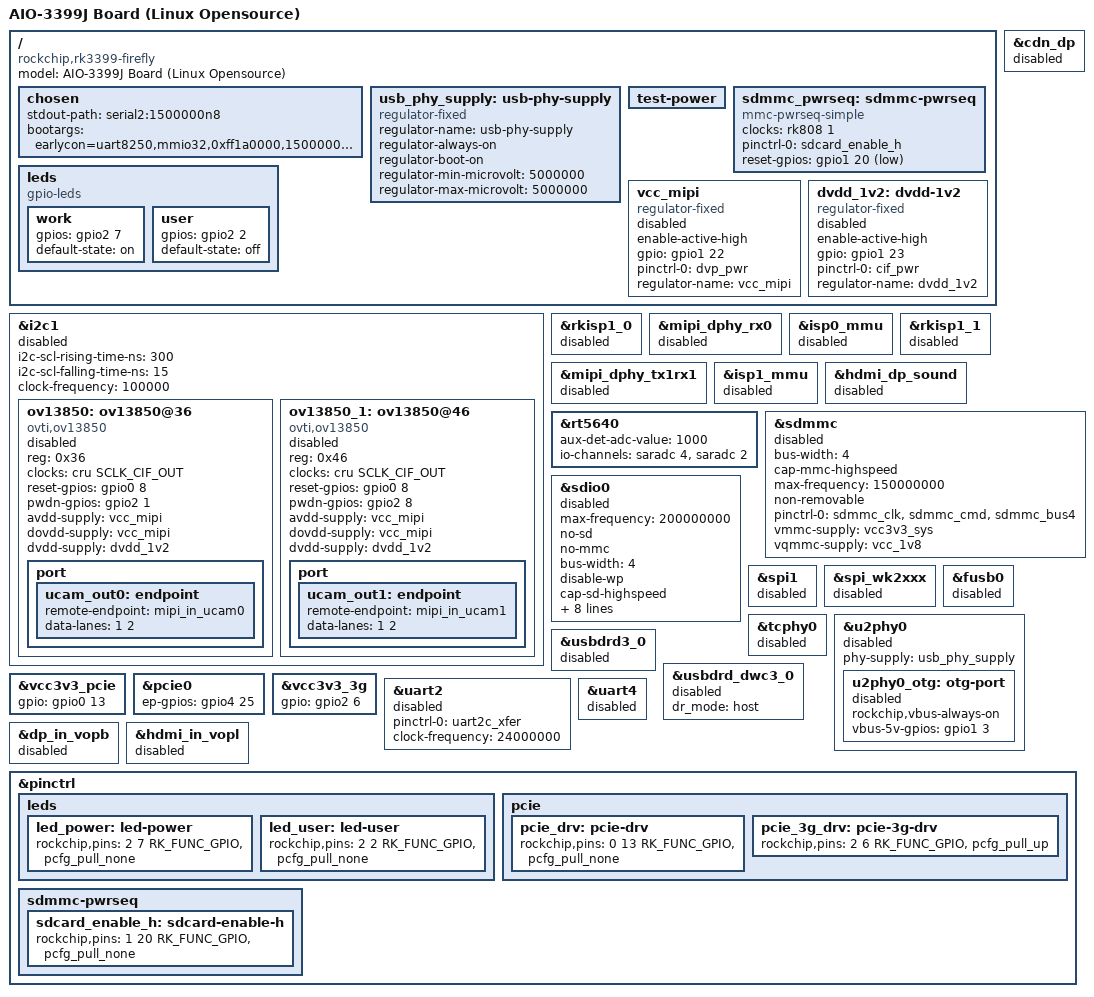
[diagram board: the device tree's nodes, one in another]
/*
 * Copyright (c) 2016 Fuzhou Rockchip Electronics Co., Ltd
 *
 * This file is dual-licensed: you can use it either under the terms
 * of the GPL or the X11 license, at your option. Note that this dual
 * licensing only applies to this file, and not this project as a
 * whole.
 *
 *  a) This file is free software; you can redistribute it and/or
 *     modify it under the terms of the GNU General Public License as
 *     published by the Free Software Foundation; either version 2 of the
 *     License, or (at your option) any later version.
 *
 *     This file is distributed in the hope that it will be useful,
 *     but WITHOUT ANY WARRANTY; without even the implied warranty of
 *     MERCHANTABILITY or FITNESS FOR A PARTICULAR PURPOSE.  See the
 *     GNU General Public License for more details.
 *
 * Or, alternatively,
 *     restriction, including without limitation the rights to use,
 *     copy, modify, merge, publish, distribute, sublicense, and/or
 *     sell copies of the Software, and to permit persons to whom the
 *     Software is furnished to do so, subject to the following
 *     conditions:
 *
 *     The above copyright notice and this permission notice shall be
 *     included in all copies or substantial portions of the Software.
 *
 *     THE SOFTWARE IS PROVIDED "AS IS", WITHOUT WARRANTY OF ANY KIND,
 *     EXPRESS OR IMPLIED, INCLUDING BUT NOT LIMITED TO THE WARRANTIES
 *     OF MERCHANTABILITY, FITNESS FOR A PARTICULAR PURPOSE AND
 *     NONINFRINGEMENT. IN NO EVENT SHALL THE AUTHORS OR COPYRIGHT
 *     HOLDERS BE LIABLE FOR ANY CLAIM, DAMAGES OR OTHER LIABILITY,
 *     WHETHER IN AN ACTION OF CONTRACT, TORT OR OTHERWISE, ARISING
 *     FROM, OUT OF OR IN CONNECTION WITH THE SOFTWARE OR THE USE OR
 *     OTHER DEALINGS IN THE SOFTWARE.
 */

/dts-v1/;

#include "rk3399-firefly-port.dtsi"

/ {
	model = "AIO-3399J Board (Linux Opensource)";
	compatible = "rockchip,rk3399-firefly", "rockchip,rk3399";

	chosen {
		stdout-path = "serial2:1500000n8";
		bootargs = "earlycon=uart8250,mmio32,0xff1a0000,1500000n8 console=ttyFIQ0 rootwait coherent_pool=1m";
	};

	/* 添加USB PHY供应器解决依赖问题 */
	usb_phy_supply: usb-phy-supply {
		compatible = "regulator-fixed";
		regulator-name = "usb-phy-supply";
		regulator-always-on;
		regulator-boot-on;
		regulator-min-microvolt = <5000000>;
		regulator-max-microvolt = <5000000>;
	};

	/* 以太网PHY供应器已在rk3399-firefly-core.dtsi中定义，此处删除重复定义 */

	test-power {
		status = "okay";
	};

	/delete-node/ vcc-sd;
	sdmmc_pwrseq: sdmmc-pwrseq {
		compatible = "mmc-pwrseq-simple";
		clocks = <&rk808 1>;
		clock-names = "ext_clock";
		pinctrl-names = "default";
		pinctrl-0 = <&sdcard_enable_h>;
		/*
		* On the module itself this is one of these (depending
		* on the actual card populated):
		* - SDIO_RESET_L_WL_REG_ON
		* - PDN (power down when low)
		*/
		reset-gpios = <&gpio1 20 GPIO_ACTIVE_LOW>; /* GPIO1_C4 */
	};

	leds {
		compatible = "gpio-leds";

		work {
			gpios = <&gpio2 7 GPIO_ACTIVE_HIGH>;
			default-state = "on";
		};

		user {
			gpios = <&gpio2 2 GPIO_ACTIVE_HIGH>;
			default-state = "off";
		};
	};

	vcc_mipi: vcc_mipi {
		compatible = "regulator-fixed";
		enable-active-high;
		gpio = <&gpio1 22 GPIO_ACTIVE_HIGH>;
		pinctrl-names = "default";
		pinctrl-0 = <&dvp_pwr>;
		regulator-name = "vcc_mipi";
		status = "disabled";
    };

	dvdd_1v2: dvdd-1v2 {
		compatible = "regulator-fixed";
		enable-active-high;
		gpio = <&gpio1 23 GPIO_ACTIVE_HIGH>;
		pinctrl-names = "default";
		pinctrl-0 = <&cif_pwr>;
		regulator-name = "dvdd_1v2";
		status = "disabled";
	};
};


&i2c1 {
	status = "disabled";
	i2c-scl-rising-time-ns = <300>;
	i2c-scl-falling-time-ns = <15>;
	clock-frequency = <100000>;

	ov13850: ov13850@36 {
		compatible = "ovti,ov13850";
		status = "disabled";
		reg = <0x36>;
		clocks = <&cru SCLK_CIF_OUT>;
		clock-names = "xvclk";

		/* conflict with csi-ctl-gpios */
		reset-gpios = <&gpio0 8 GPIO_ACTIVE_HIGH>;	/*GPIO0_B0 MIP_RST*/
		pwdn-gpios = <&gpio2 1 GPIO_ACTIVE_HIGH>;	/*GPIO2_A1  DVP_PDN1_H*/
		pinctrl-names = "rockchip,camera_default", "rockchip,camera_sleep";
		//pinctrl-0 = <&cif_clkout>;
		//pinctrl-0 = <&pwdn_cam0 &mipi_rst>;
		
		//pinctrl-0 = <&pwdn_cam0>;
		//pinctrl-1 = <&cam0_default_pins>;
		//pinctrl-2 = <&cam0_sleep_pins>;

		avdd-supply = <&vcc_mipi>; /* GPIO1_C6 CIF_PWR  AGND*/
		dovdd-supply = <&vcc_mipi>; /* GPIO1_C6 CIF_PWR  AGND */
		dvdd-supply = <&dvdd_1v2>; /* GPIO1_C7 DVP_PWR DVDD_1V2 */

		port {
			ucam_out0: endpoint {
				remote-endpoint = <&mipi_in_ucam0>;
				data-lanes = <1 2>;
			};
		};
	};

	ov13850_1: ov13850@46 {
		compatible = "ovti,ov13850";
		status = "disabled";
		reg = <0x46>;
		clocks = <&cru SCLK_CIF_OUT>;
		clock-names = "xvclk";

		/* conflict with csi-ctl-gpios */
		reset-gpios = <&gpio0 8 GPIO_ACTIVE_HIGH>; /*GPIO0_B0 MIP_RST*/
		pwdn-gpios = <&gpio2 8 GPIO_ACTIVE_HIGH>;	/*GPIO2_B0 DVP_PDN0*/
		pinctrl-names = "rockchip,camera_default", "rockchip,camera_sleep";
		//pinctrl-0 = <&cif_clkout>;
	//	pinctrl-0 = <&pwdn_cam1>;
		//pinctrl-1 = <&cam0_default_pins>;
		//pinctrl-2 = <&cam0_sleep_pins>;

		avdd-supply = <&vcc_mipi>; /* VCC28_MIPI */
		dovdd-supply = <&vcc_mipi>; /* VCC18_MIPI */
		dvdd-supply = <&dvdd_1v2>; /* DVDD_1V2 */

		port {
			ucam_out1: endpoint {
				remote-endpoint = <&mipi_in_ucam1>;
				data-lanes = <1 2>;
			};
		};
	};
};


&vcc_mipi {
	status = "disabled";
};

&dvdd_1v2 {
	status = "disabled";
};

&ov13850 {
	status = "disabled";
};

&ov13850_1 {
	status = "disabled";
};

&rkisp1_0 {
	status = "disabled";
};

&mipi_dphy_rx0 {
	status = "disabled";
};

&isp0_mmu {
	status = "disabled";
};

&rkisp1_1 {
	status = "disabled";
};

&mipi_dphy_tx1rx1 {
	status = "disabled";
};

&isp1_mmu {
	status = "disabled";
};





&cdn_dp {
	status = "disabled";
};

&hdmi_dp_sound {
	status = "disabled";
};

&rt5640 {
    aux-det-adc-value = <1000>;
    io-channels = <&saradc 4>, <&saradc 2>;
    io-channel-names = "hp-det", "aux-det";
};

&sdmmc {
	bus-width = <4>;
	cap-mmc-highspeed;
	max-frequency = <150000000>;
	non-removable;
	pinctrl-names = "default";
	pinctrl-0 = <&sdmmc_clk &sdmmc_cmd &sdmmc_bus4>;
	vmmc-supply = <&vcc3v3_sys>;
	vqmmc-supply = <&vcc_1v8>;
	status = "disabled";
};

&sdio0 {
	max-frequency = <200000000>;
	no-sd;
	no-mmc;
	bus-width = <4>;
	disable-wp;
	cap-sd-highspeed;
	keep-power-in-suspend;
	mmc-pwrseq = <&sdio_pwrseq>;
	non-removable;
	num-slots = <1>;
	pinctrl-names = "default";
	pinctrl-0 = <&sdio0_bus4 &sdio0_cmd &sdio0_clk>;
	sd-uhs-sdr104;
	vmmc-supply = <&vcc3v3_sys>;
	vqmmc-supply = <&vcc_1v8>;
	status = "disabled";
};

&spi1 {
    status = "disabled";
};

&spi_wk2xxx {
    status = "disabled";
};

&fusb0 {
    status = "disabled";
};

&tcphy0 {
    status = "disabled";
    /delete-property/ extcon;
};

&u2phy0 {
    status = "disabled";
    phy-supply = <&usb_phy_supply>;  /* 添加PHY供应器 */
    /delete-property/ extcon;

    u2phy0_otg: otg-port {
        rockchip,vbus-always-on;
        vbus-5v-gpios = <&gpio1 3 GPIO_ACTIVE_HIGH>;
        status = "disabled";
    };
};

&usbdrd3_0 {
    status = "disabled";
    /delete-property/ extcon;
};

&usbdrd_dwc3_0 {
	status = "disabled";
	dr_mode = "host";
};

&vcc3v3_pcie {
    gpio = <&gpio0 13 GPIO_ACTIVE_HIGH>;
};

&pcie0 {
	ep-gpios = <&gpio4 25 GPIO_ACTIVE_HIGH>;
};

&vcc3v3_3g {
    gpio = <&gpio2 6 GPIO_ACTIVE_HIGH>;
};

&uart2 {
	pinctrl-names = "default";
	pinctrl-0 = <&uart2c_xfer>;
	status = "disabled";
	/* Set clock frequency to 24MHz for proper 1500000 baud rate calculation */
	clock-frequency = <24000000>;
};

&uart4 {
    status = "disabled";
};

&dp_in_vopb {
	status = "disabled";
};

&hdmi_in_vopl {
	status = "disabled";
};

// &wdt {
//	status = "disabled";
// };

&pinctrl {
	leds {
		led_power: led-power {
			rockchip,pins =
				<2 7 RK_FUNC_GPIO &pcfg_pull_none>;
		};

		led_user: led-user {
			rockchip,pins =
				<2 2 RK_FUNC_GPIO &pcfg_pull_none>;
		};
	};

	pcie {
		pcie_drv: pcie-drv {
			rockchip,pins =
				<0 13 RK_FUNC_GPIO &pcfg_pull_none>;
		};

		pcie_3g_drv: pcie-3g-drv {
			rockchip,pins =
				<2 6 RK_FUNC_GPIO &pcfg_pull_up>;
		};
	};

	sdmmc-pwrseq {
		sdcard_enable_h: sdcard-enable-h {
			rockchip,pins =
				<1 20 RK_FUNC_GPIO &pcfg_pull_none>;
		};
	};
};
